# CY8C5267AXI_LP051 register map
File version: 0.1
CY8C52LP
Registers are 8-bit, read-write, no defined reset value unless marked. A register's access mark holds for its fields unless they carry their own. Offsets are from the block's base; lines under a group give offsets from that group; [hi:lo] are bit positions; {n}, {i} and the like mark numbered series; 'fields as' and 'values as' point back to an identical list; <NAME> marks a mode.

## Memory map
0x00000000 DataIn_Port5
0x00000000 DataOut_Port1
0x00000000 DataOut_Port5
0x00000000 DataIn_Port6
0x00000000 DataOut_Port4
0x00000000 DataIn_Port1
0x00000000 DataIn_Port15
0x00000000 DataOut_Port12
0x00000000 DataOut_Port15
0x00000000 DataIn_Port12
0x00000000 DataOut_Port6
0x00000000 DataIn_Port2
0x00000000 I2C_EEPROM
0x00000000 USBUART — USBFS
0x00000000 DataIn_Port3
0x00000000 DataIn_Port0
0x00000000 DataOut_Port0
0x00000000 Dir_Ctl
0x00000000 DataIn_Port4
0x00000000 DataOut_Port3
0x00000000 DataOut_Port2

## DataIn_Port5
Base 0x00000000
0x40006569 DataIn_Port5_STATUS_REG
0x40006589 DataIn_Port5_MASK_REG
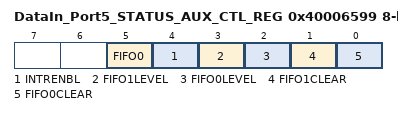
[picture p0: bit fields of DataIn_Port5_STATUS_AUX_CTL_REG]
0x40006599 DataIn_Port5_STATUS_AUX_CTL_REG
  [5] FIFO0 — FIFO0 clear
    1=ENABLED (Enable counter); 0=DISABLED (Disable counter)
  [4] INTRENBL — Enables or disables the Interrupt
    1=ENABLED (Interrupt enabled); 0=DISABLED (Interrupt disabled)
  [3] FIFO1LEVEL — FIFO level
    1=ENABLED (FIFO LVL: input mode: FIFO at least 1/2 empty; output mode: FIFO at least 1/2 full); 0=DISABLED (FIFO LVL: input mode: FIFO not full; output mode: FIFO not empty)
  [2] FIFO0LEVEL — FIFO level
    values as FIFO1LEVEL
  [1] FIFO1CLEAR — FIFO clear
    1=ENABLED (Clear FIFO state); 0=DISABLED (Normal FIFO operation)
  [0] FIFO0CLEAR — FIFO clear
    values as FIFO1CLEAR

## DataOut_Port1
Base 0x00000000
0x40006579 DataOut_Port1_CONTROL_REG

## DataOut_Port5
Base 0x00000000
0x40006578 DataOut_Port5_CONTROL_REG

## DataIn_Port6
Base 0x00000000
0x40006468 DataIn_Port6_STATUS_REG
0x40006488 DataIn_Port6_MASK_REG
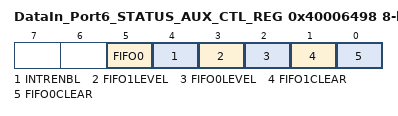
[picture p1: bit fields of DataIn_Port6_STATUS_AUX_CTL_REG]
0x40006498 DataIn_Port6_STATUS_AUX_CTL_REG
  [5] FIFO0 — FIFO0 clear
    1=ENABLED (Enable counter); 0=DISABLED (Disable counter)
  [4] INTRENBL — Enables or disables the Interrupt
    1=ENABLED (Interrupt enabled); 0=DISABLED (Interrupt disabled)
  [3] FIFO1LEVEL — FIFO level
    1=ENABLED (FIFO LVL: input mode: FIFO at least 1/2 empty; output mode: FIFO at least 1/2 full); 0=DISABLED (FIFO LVL: input mode: FIFO not full; output mode: FIFO not empty)
  [2] FIFO0LEVEL — FIFO level
    values as FIFO1LEVEL
  [1] FIFO1CLEAR — FIFO clear
    1=ENABLED (Clear FIFO state); 0=DISABLED (Normal FIFO operation)
  [0] FIFO0CLEAR — FIFO clear
    values as FIFO1CLEAR

## DataOut_Port4
Base 0x00000000
0x40006473 DataOut_Port4_CONTROL_REG

## DataIn_Port1
Base 0x00000000
0x40006568 DataIn_Port1_STATUS_REG
0x40006588 DataIn_Port1_MASK_REG
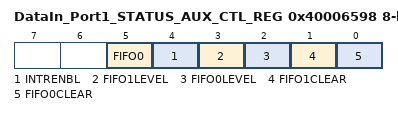
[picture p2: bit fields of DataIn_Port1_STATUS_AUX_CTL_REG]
0x40006598 DataIn_Port1_STATUS_AUX_CTL_REG
  [5] FIFO0 — FIFO0 clear
    1=ENABLED (Enable counter); 0=DISABLED (Disable counter)
  [4] INTRENBL — Enables or disables the Interrupt
    1=ENABLED (Interrupt enabled); 0=DISABLED (Interrupt disabled)
  [3] FIFO1LEVEL — FIFO level
    1=ENABLED (FIFO LVL: input mode: FIFO at least 1/2 empty; output mode: FIFO at least 1/2 full); 0=DISABLED (FIFO LVL: input mode: FIFO not full; output mode: FIFO not empty)
  [2] FIFO0LEVEL — FIFO level
    values as FIFO1LEVEL
  [1] FIFO1CLEAR — FIFO clear
    1=ENABLED (Clear FIFO state); 0=DISABLED (Normal FIFO operation)
  [0] FIFO0CLEAR — FIFO clear
    values as FIFO1CLEAR

## DataIn_Port15
Base 0x00000000
0x40006566 DataIn_Port15_STATUS_REG
0x40006586 DataIn_Port15_MASK_REG
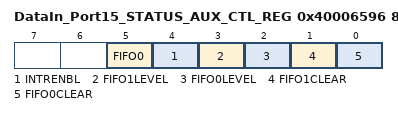
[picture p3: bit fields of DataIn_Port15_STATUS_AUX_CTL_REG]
0x40006596 DataIn_Port15_STATUS_AUX_CTL_REG
  [5] FIFO0 — FIFO0 clear
    1=ENABLED (Enable counter); 0=DISABLED (Disable counter)
  [4] INTRENBL — Enables or disables the Interrupt
    1=ENABLED (Interrupt enabled); 0=DISABLED (Interrupt disabled)
  [3] FIFO1LEVEL — FIFO level
    1=ENABLED (FIFO LVL: input mode: FIFO at least 1/2 empty; output mode: FIFO at least 1/2 full); 0=DISABLED (FIFO LVL: input mode: FIFO not full; output mode: FIFO not empty)
  [2] FIFO0LEVEL — FIFO level
    values as FIFO1LEVEL
  [1] FIFO1CLEAR — FIFO clear
    1=ENABLED (Clear FIFO state); 0=DISABLED (Normal FIFO operation)
  [0] FIFO0CLEAR — FIFO clear
    values as FIFO1CLEAR
